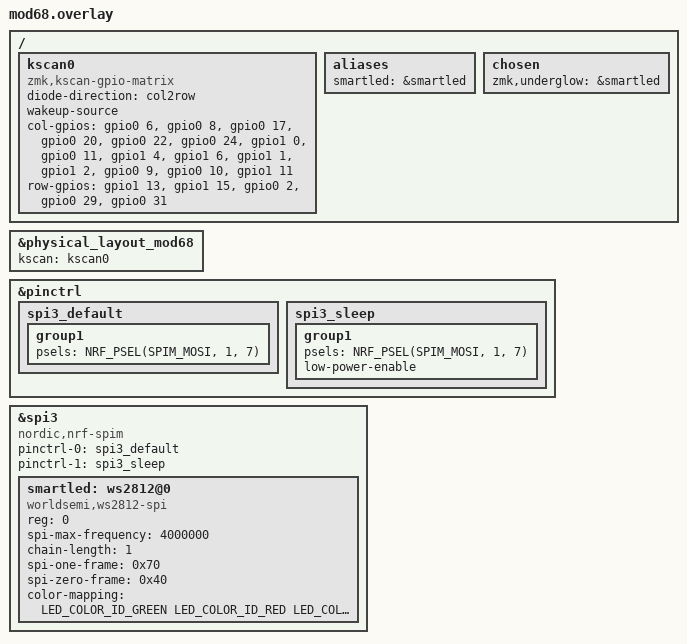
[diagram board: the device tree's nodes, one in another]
#include "mod68.dtsi"
#include <dt-bindings/led/led.h>

/ {
    kscan0: kscan0 {
        compatible = "zmk,kscan-gpio-matrix";
        diode-direction = "col2row";
        wakeup-source;

        /* col2row => le COLONNE sono uscite, le RIGHE ingressi (pull-down).
         * Catodo del diodo (fascetta) verso la RIGA.
         */
        col-gpios
            = <&gpio0  6 GPIO_ACTIVE_HIGH>   /* D1  / TX        */
            , <&gpio0  8 GPIO_ACTIVE_HIGH>   /* D0  / RX        */
            , <&gpio0 17 GPIO_ACTIVE_HIGH>   /* D2              */
            , <&gpio0 20 GPIO_ACTIVE_HIGH>   /* D3              */
            , <&gpio0 22 GPIO_ACTIVE_HIGH>   /* D4              */
            , <&gpio0 24 GPIO_ACTIVE_HIGH>   /* D5              */
            , <&gpio1  0 GPIO_ACTIVE_HIGH>   /* D6              */
            , <&gpio0 11 GPIO_ACTIVE_HIGH>   /* D7              */
            , <&gpio1  4 GPIO_ACTIVE_HIGH>   /* D8              */
            , <&gpio1  6 GPIO_ACTIVE_HIGH>   /* D9              */
            , <&gpio1  1 GPIO_ACTIVE_HIGH>   /* pad extra P1.01 */
            , <&gpio1  2 GPIO_ACTIVE_HIGH>   /* pad extra P1.02 */
            , <&gpio0  9 GPIO_ACTIVE_HIGH>   /* D10 (NFC1)      */
            , <&gpio0 10 GPIO_ACTIVE_HIGH>   /* D16 (NFC2)      */
            , <&gpio1 11 GPIO_ACTIVE_HIGH>   /* D14             */
            ;

        row-gpios
            = <&gpio1 13 (GPIO_ACTIVE_HIGH | GPIO_PULL_DOWN)>   /* D15      */
            , <&gpio1 15 (GPIO_ACTIVE_HIGH | GPIO_PULL_DOWN)>   /* D18 / A0 */
            , <&gpio0  2 (GPIO_ACTIVE_HIGH | GPIO_PULL_DOWN)>   /* D19 / A1 */
            , <&gpio0 29 (GPIO_ACTIVE_HIGH | GPIO_PULL_DOWN)>   /* D20 / A2 */
            , <&gpio0 31 (GPIO_ACTIVE_HIGH | GPIO_PULL_DOWN)>   /* D21 / A3 */
            ;
    };
};

&physical_layout_mod68 {
    kscan = <&kscan0>;
};

/* ---- LED RGB WS2812 (caps lock) su P1.07, unico pin rimasto libero ---- */

&pinctrl {
    spi3_default: spi3_default {
        group1 {
            psels = <NRF_PSEL(SPIM_MOSI, 1, 7)>;
        };
    };

    spi3_sleep: spi3_sleep {
        group1 {
            psels = <NRF_PSEL(SPIM_MOSI, 1, 7)>;
            low-power-enable;
        };
    };
};

&spi3 {
    compatible = "nordic,nrf-spim";
    status = "okay";

    pinctrl-0 = <&spi3_default>;
    pinctrl-1 = <&spi3_sleep>;
    pinctrl-names = "default", "sleep";

    smartled: ws2812@0 {
        compatible = "worldsemi,ws2812-spi";

        /* SPI */
        reg = <0>; /* ignorato, ma richiesto dal binding SPI */
        spi-max-frequency = <4000000>;

        /* WS2812 */
        chain-length = <1>; /* numero di LED */
        spi-one-frame = <0x70>;
        spi-zero-frame = <0x40>;
        color-mapping = <LED_COLOR_ID_GREEN
                         LED_COLOR_ID_RED
                         LED_COLOR_ID_BLUE>;
    };
};

/ {
    aliases {
        smartled = &smartled;
    };

    chosen {
        zmk,underglow = &smartled;
    };
};
